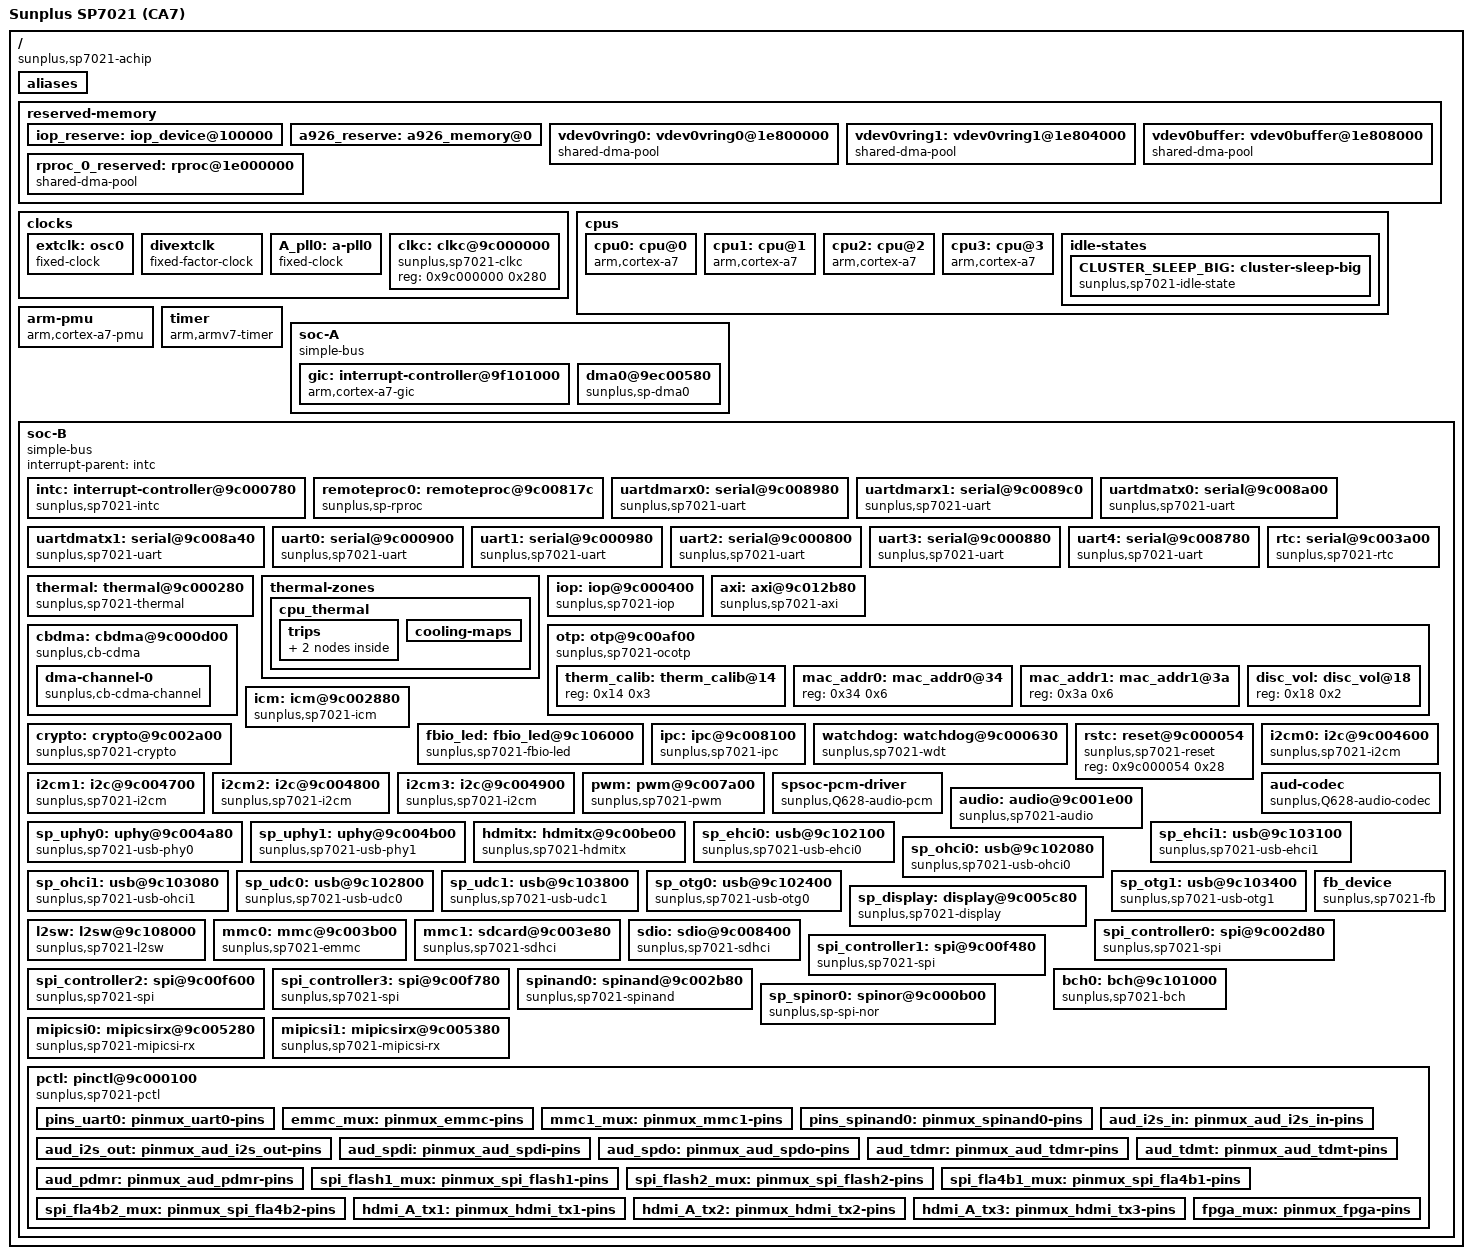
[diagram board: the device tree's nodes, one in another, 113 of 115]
// SPDX-License-Identifier: GPL-2.0
/*
 * Device Tree Source (include) for Sunplus SP7021 SoC
 *                (Common portion)
 *
 * Copyright (C) 2021 Sunplus Technology Co.
 */

/dts-v1/;

#include <dt-bindings/clock/sp-sp7021.h>
#include <dt-bindings/interrupt-controller/arm-gic.h>
#include <dt-bindings/interrupt-controller/sp7021-intc.h>
#include <dt-bindings/interrupt-controller/irq.h>
#include <dt-bindings/reset/sp-sp7021.h>
#include <dt-bindings/gpio/gpio.h>
#include <dt-bindings/pinctrl/sppctl-sp7021.h>

#ifndef ENABLE_DMARX0
#define ENABLE_DMARX0 1
#endif
#ifndef ENABLE_DMARX1
#define ENABLE_DMARX1 1
#endif
#ifndef ENABLE_DMATX0
#define ENABLE_DMATX0 1
#endif
#ifndef ENABLE_DMATX1
#define ENABLE_DMATX1 1
#endif

/ {
	model = "Sunplus SP7021 (CA7)";
	compatible = "sunplus,sp7021-achip";

	interrupt-parent = <&gic>;

	#address-cells = <1>;
	#size-cells = <1>;

	aliases {
#ifdef ENABLE_DMARX0
		serial10 = &uartdmarx0;
#endif
#ifdef ENABLE_DMARX1
		serial11 = &uartdmarx1;
#endif
#ifdef ENABLE_DMATX0
		serial20 = &uartdmatx0;
#endif
#ifdef ENABLE_DMATX1
		serial21 = &uartdmatx1;
#endif

		serial0 = &uart0;
		serial1 = &uart1;
		serial2 = &uart2;
		serial3 = &uart3;
		serial4 = &uart4;

#if 0
		/* Timer tests: */
		/* 1. Enable device tree for timers. */
		/* 2. Enable sp_timer_test in drivers/misc/Makefile */
		stc0 = &sp_tmr_tst0;
		stc1 = &sp_tmr_tst1;
		stc2 = &sp_tmr_tst2;
		stc3 = &sp_tmr_tst3;
#endif

		i2c0 = &i2cm0;
		i2c1 = &i2cm1;
		i2c2 = &i2cm2;
		i2c3 = &i2cm3;

		sp-spi0 = &spi_controller0;
		sp-spi1 = &spi_controller1;
		sp-spi2 = &spi_controller2;
		sp-spi3 = &spi_controller3;

		spi0 = &sp_spinor0;
	};

	reserved-memory {
		#address-cells = <1>;
		#size-cells = <1>;
		ranges;

		iop_reserve: iop_device@100000 {
			reg = <0x00100000 0x00100000>;  // SP_IOP_RESERVE_BASE SP_IOP_RESERVE_SIZE
			no-map;
		};

		a926_reserve: a926_memory@0 {
			reg = <0x00000000 0x00100000>;
			no-map;
		};

		/* reserved for remoteproc */
		vdev0vring0: vdev0vring0@1e800000 {
			compatible = "shared-dma-pool";
			reg = <0x1e800000 0x4000>;
			no-map;
		};
		vdev0vring1: vdev0vring1@1e804000 {
			compatible = "shared-dma-pool";
			reg = <0x1e804000 0x4000>;
			no-map;
		};
		vdev0buffer: vdev0buffer@1e808000 {
			compatible = "shared-dma-pool";
			reg = <0x1e808000 0x100000>;
			no-map;
		};
		rproc_0_reserved: rproc@1e000000 {
			compatible = "shared-dma-pool";
			reg = <0x1e000000 0x800000>;
			no-map;
		};
	};

	clocks {
		#address-cells = <1>;
		#size-cells = <1>;
		ranges;

		extclk: osc0 {
			compatible = "fixed-clock";
			#clock-cells = <0>;
			clock-frequency = <27000000>;
			clock-output-names = "extclk";

		};

		divextclk: divextclk {
			compatible = "fixed-factor-clock";
			#clock-cells = <0>;
			clocks  = <&extclk>;
			clock-mult = <1>;
			clock-div = <2>;
			clock-output-names = "extdivclk";
		};

		A_pll0: a-pll0 {
			compatible = "fixed-clock";
			#clock-cells = <0>;
			clock-frequency = <2000000000>;
			clock-output-names = "A_pll0";
		};

		clkc: clkc@9c000000 {
			compatible = "sunplus,sp7021-clkc";
			reg = <0x9c000000 0x280>;
			#clock-cells = <1>;
		};
	};

	cpus {
		#address-cells = <1>;
		#size-cells = <0>;

		cpu0: cpu@0 {
			compatible = "arm,cortex-a7";
			device_type = "cpu";
			reg = <0>;
			clock-frequency = <931000000>;
			cpu-idle-states = <&CLUSTER_SLEEP_BIG>;
		};
		cpu1: cpu@1 {
			compatible = "arm,cortex-a7";
			device_type = "cpu";
			reg = <1>;
			enable-method = "sunplus,sc-smp";
			cpu-boot-reg = <0x9ea7fff0>;
			clock-frequency = <931000000>;
			cpu-idle-states = <&CLUSTER_SLEEP_BIG>;
		};
		cpu2: cpu@2 {
			compatible = "arm,cortex-a7";
			device_type = "cpu";
			reg = <2>;
			enable-method = "sunplus,sc-smp";
			cpu-boot-reg = <0x9ea7ffec>;
			clock-frequency = <931000000>;
			cpu-idle-states = <&CLUSTER_SLEEP_BIG>;
		};
		cpu3: cpu@3 {
			compatible = "arm,cortex-a7";
			device_type = "cpu";
			reg = <3>;
			enable-method = "sunplus,sc-smp";
			cpu-boot-reg = <0x9ea7ffe8>;
			clock-frequency = <931000000>;
			cpu-idle-states = <&CLUSTER_SLEEP_BIG>;
		};

		idle-states {
			CLUSTER_SLEEP_BIG: cluster-sleep-big {
				compatible = "sunplus,sp7021-idle-state";
				//local-timer-stop;
				entry-latency-us = <8000>;
				exit-latency-us = <700>;
				min-residency-us = <9000>;
			};
#if 0
			CLUSTER_SLEEP_LITTLE: cluster-sleep-little {
				compatible = "sunplus,sp7021-idle-state";
				local-timer-stop;
				entry-latency-us = <1000>;
				exit-latency-us = <500>;
				min-residency-us = <2500>;
			};
#endif
		};
	};

	arm-pmu {
		compatible = "arm,cortex-a7-pmu";
		interrupts = <GIC_SPI 219 IRQ_TYPE_LEVEL_HIGH>,
			     <GIC_SPI 220 IRQ_TYPE_LEVEL_HIGH>,
			     <GIC_SPI 221 IRQ_TYPE_LEVEL_HIGH>,
			     <GIC_SPI 222 IRQ_TYPE_LEVEL_HIGH>;
		interrupt-affinity = <&cpu0>, <&cpu1>, <&cpu2>, <&cpu3>;
	};

	timer: timer {
		compatible = "arm,armv7-timer";
		interrupts = <GIC_PPI 13 (GIC_CPU_MASK_SIMPLE(4) | IRQ_TYPE_LEVEL_LOW)>,
			     <GIC_PPI 14 (GIC_CPU_MASK_SIMPLE(4) | IRQ_TYPE_LEVEL_LOW)>,
			     <GIC_PPI 11 (GIC_CPU_MASK_SIMPLE(4) | IRQ_TYPE_LEVEL_LOW)>,
			     <GIC_PPI 10 (GIC_CPU_MASK_SIMPLE(4) | IRQ_TYPE_LEVEL_LOW)>;
		clock-frequency = <27000000>;
		arm,cpu-registers-not-fw-configured;
	};

	/* A modules */
	soc-A {
		compatible = "simple-bus";
		#address-cells = <1>;
		#size-cells = <1>;
		ranges;

		gic: interrupt-controller@9f101000 {
			compatible = "arm,cortex-a7-gic";
			reg = <0x9f101000 0x1000>, <0x9f102000 0x2000>, <0x9f104000 0x2000>, <0x9f106000 0x2000>;
			interrupt-controller;
			#interrupt-cells = <3>;
		};

		dma0@9ec00580 {
			compatible = "sunplus,sp-dma0";
			reg = <0x9ec00580 0x180>; /* G11 ~ G13 */
			interrupt-parent = <&gic>;
			interrupts = <GIC_SPI 8  IRQ_TYPE_EDGE_RISING>, /* ch0_job_done */
				     <GIC_SPI 9  IRQ_TYPE_EDGE_RISING>, /* ch1_job_done */
				     <GIC_SPI 10 IRQ_TYPE_EDGE_RISING>, /* ch2_job_done */
				     <GIC_SPI 11 IRQ_TYPE_EDGE_RISING>, /* ch3_job_done */
				     <GIC_SPI 12 IRQ_TYPE_EDGE_RISING>, /* ch4_job_done */
				     <GIC_SPI 13 IRQ_TYPE_EDGE_RISING>, /* ch5_job_done */
				     <GIC_SPI 14 IRQ_TYPE_EDGE_RISING>, /* ch6_job_done */
				     <GIC_SPI 15 IRQ_TYPE_EDGE_RISING>, /* ch7_job_done */
				     <GIC_SPI 16 IRQ_TYPE_EDGE_RISING>; /* addr_exp_err */
		};
#if 0
		/* Each Cortex A-7 has its own system timer, it's not required if armv7-timer is enabled. */
		/* This timer will be used in sp_timer_test.c */
		timer@9ec00980 {
			compatible = "sunplus,sp-stc";
			reg = <0x9ec00980 0x80>;
			interrupt-parent = <&gic>;
			interrupts = <GIC_SPI 1 IRQ_TYPE_EDGE_RISING>, /* timer0 */
				     <GIC_SPI 2 IRQ_TYPE_EDGE_RISING>, /* timer1 */
				     <GIC_SPI 3 IRQ_TYPE_EDGE_RISING>, /* timer2 */
				     <GIC_SPI 4 IRQ_TYPE_EDGE_RISING>; /* timer3 */
		};
#endif
#if 0
		sp_tmr_tst@9ec00980 {
			compatible = "sunplus,sp-tmr-tst";
			reg = <0x9ec00980 0x80>;
			interrupt-parent = <&gic>;
			interrupts = <GIC_SPI 1 IRQ_TYPE_EDGE_RISING>, /* timer0 */
				     <GIC_SPI 2 IRQ_TYPE_EDGE_RISING>, /* timer1 */
				     <GIC_SPI 3 IRQ_TYPE_EDGE_RISING>, /* timer2 */
				     <GIC_SPI 4 IRQ_TYPE_EDGE_RISING>; /* timer3 */
		};
#endif
#if 0
		axi: axi@sp_axi {
			compatible = "sunplus,sp7021-axi";
			reg = <0x9ec12b80 0x80>, <0x9ec12c00 0x80>, <0x9ec12c80 0x80>,
			      <0x9ec12d00 0x80>, <0x9ec12d80 0x80>, <0x9ec12e00 0x80>,
			      <0x9ec12e80 0x80>, <0x9ec12f00 0x80>, <0x9ec12f80 0x80>,
			      <0x9ec13000 0x80>, <0x9ec13080 0x80>, <0x9ec13100 0x80>,
			      <0x9c000d00 0x80>;
			reg-names = "axi_mon", "axi_0", "axi_1",
				    "axi_2", "axi_3", "axi_4",
				    "axi_5", "axi_6", "axi_7",
				    "axi_8", "axi_9", "axi_10",
				    "axi_cbdma";
			interrupt-parent = <&gic>;
			interrupts = <GIC_SPI 23 IRQ_TYPE_EDGE_RISING>;
			clocks = <&clkc AXI_GLOBAL>;
			resets = <&rstc RST_AXI_GLOBAL>;
		};
#endif
	};

	/* B modules */
	soc-B {
		compatible = "simple-bus";
		#address-cells = <1>;
		#size-cells = <1>;
		ranges;

		interrupt-parent = <&intc>;

		intc: interrupt-controller@9c000780 {
			compatible = "sunplus,sp7021-intc";
			interrupt-controller;
			#interrupt-cells = <2>;
			reg = <0x9c000780 0x80>, <0x9c000a80 0x80>;
			interrupt-parent = <&gic>;
			interrupts = <GIC_SPI 5 IRQ_TYPE_LEVEL_HIGH>, /* EXT_INT0 */
				     <GIC_SPI 6 IRQ_TYPE_LEVEL_HIGH>; /* EXT_INT1 */
			sunplus,ext0-mask = <0xf>; /* core0-3 */
			sunplus,ext1-mask = <0xe>; /* core1-3 */
		};

		remoteproc0: remoteproc@9c00817c {
			compatible = "sunplus,sp-rproc";
			firmware = "firmware";
			reg = <0x9c00817c 4>, /* mbox G258.31 */
				<0x9e809ff8 4>; /* boot A926 */
			interrupt-parent = <&intc>;
			interrupts = <189 IRQ_TYPE_EDGE_RISING>; /* ACHIPCPU0_DIRECT_INT7 */
			resets = <&rstc RST_A926>;
			memory-region = <&rproc_0_reserved>, <&vdev0buffer>, <&vdev0vring0>, <&vdev0vring1>;
		};

#ifdef ENABLE_DMARX0
		/* DMA Rx for UARTx */
		uartdmarx0: serial@9c008980 {
			compatible = "sunplus,sp7021-uart";
			reg = <0x9c008980 0x40>;
			interrupt-parent = <&intc>;
			interrupts = <138 IRQ_TYPE_LEVEL_HIGH>;
			clocks = <&clkc UADMA>, <&clkc PERI0>;
			clock-names = "UADMA", "PERI0";
			resets = <&rstc RST_UADMA>;
			which-uart = <1>;
		};
#endif
#ifdef ENABLE_DMARX1
		uartdmarx1: serial@9c0089c0 {
			compatible = "sunplus,sp7021-uart";
			reg = <0x9c0089c0 0x40>;
			interrupt-parent = <&intc>;
			interrupts = <139 IRQ_TYPE_LEVEL_HIGH>;
			clocks = <&clkc UADMA>,	<&clkc PERI1>;
			clock-names = "UADMA", "PERI1";
			resets = <&rstc RST_UADMA>;
			which-uart = <2>;
		};
#endif
#ifdef ENABLE_DMATX0
		/* DMA Tx for UARTx */
		uartdmatx0: serial@9c008a00 {
			compatible = "sunplus,sp7021-uart";
			reg = <0x9c008a00 0x40>, <0x9c008880 0x80>;
			clocks = <&clkc HWUA>, <&clkc PERI0>;
			clock-names = "HWUA", "PERI0";
			resets = <&rstc RST_HWUA>;
			which-uart = <1>;
		};
#endif
#ifdef ENABLE_DMATX1
		uartdmatx1: serial@9c008a40 {
			compatible = "sunplus,sp7021-uart";
			reg = <0x9c008a40 0x40>, <0x9c008900 0x80>;
			clocks = <&clkc HWUA>, <&clkc PERI1>;
			clock-names = "HWUA", "PERI1";
			resets = <&rstc RST_HWUA>;
			which-uart = <2>;
		};
#endif

		uart0: serial@9c000900 {
			compatible = "sunplus,sp7021-uart";
			reg = <0x9c000900 0x80>;
			interrupt-parent = <&intc>;
			interrupts = <53 IRQ_TYPE_LEVEL_HIGH>;
			clocks = <&clkc UA0>;
			resets = <&rstc RST_UA0>;
			pinctrl-names = "default";
			pinctrl-0 = <&pins_uart0>;
		};

		uart1: serial@9c000980 {
			compatible = "sunplus,sp7021-uart";
			reg = <0x9c000980 0x80>;
			interrupt-parent = <&intc>;
			interrupts = <54 IRQ_TYPE_LEVEL_HIGH>;
			clocks = <&clkc UA1>;
			resets = <&rstc RST_UA1>;
		};

		uart2: serial@9c000800 {
			compatible = "sunplus,sp7021-uart";
			reg = <0x9c000800 0x80>;
			interrupt-parent = <&intc>;
			interrupts = <55 IRQ_TYPE_LEVEL_HIGH>;
			clocks = <&clkc UA2>;
			resets = <&rstc RST_UA2>;
		};

		uart3: serial@9c000880 {
			compatible = "sunplus,sp7021-uart";
			reg = <0x9c000880 0x80>;
			interrupt-parent = <&intc>;
			interrupts = <56 IRQ_TYPE_LEVEL_HIGH>;
			clocks = <&clkc UA3>;
			resets = <&rstc RST_UA3>;
		};

		uart4: serial@9c008780 {
			compatible = "sunplus,sp7021-uart";
			reg = <0x9c008780 0x80>;
			interrupt-parent = <&intc>;
			interrupts = <134 IRQ_TYPE_LEVEL_HIGH>;
			clocks = <&clkc UA4>;
			resets = <&rstc RST_UA4>;
		};

		rtc: serial@9c003a00 {
			compatible = "sunplus,sp7021-rtc";
			reg = <0x9c003a00 0x80>;
			reg-names = "rtc_reg";
			clocks = <&clkc RTC>;
			resets = <&rstc RST_RTC>;
			interrupt-parent = <&intc>;
			interrupts = <163 IRQ_TYPE_EDGE_RISING>;
		};

		thermal: thermal@9c000280 {
			compatible = "sunplus,sp7021-thermal";
			reg = <0x9c000280 0x80>;
			#thermal-sensor-cells = <0>;
			nvmem-cell-names = "therm_calib";
			nvmem-cells = <&therm_calib>;
		};

		thermal-zones {
			cpu_thermal: cpu_thermal {
				polling-delay-passive = <1000>; /* milliseconds */
				polling-delay = <1000>; /* milliseconds */

				thermal-sensors = <&thermal 0>;
				sustainable-power = <100000>;

				trips {
					cpu-hott {
						temperature = <80000>;
						hysteresis  = <1000>;
						type        = "hot";
					};
					cpu-crit {
						temperature = <85000>;
						hysteresis  = <0>;
						type        = "critical";
					};
				};
				cooling-maps {
					/* insert there: slowdown CPU for cpu-hott */
				};
			};
		};

		iop: iop@9c000400 {
			compatible = "sunplus,sp7021-iop";
			reg = <0x9c000400 0x80>, <0x9c000000 0x80>, <0x9c000f00 0x80>, <0x9c003100 0x80>, <0x9c012b80 0x80>;
			reg-names = "iop", "iop_moon0", "iop_qctl", "iop_pmc", "axi_mon";
			interrupt-parent = <&intc>;
			interrupts = <41 IRQ_TYPE_LEVEL_HIGH>, <42 IRQ_TYPE_LEVEL_HIGH>;
			memory-region = <&iop_reserve>;
		};

		axi: axi@9c012b80 {
			compatible = "sunplus,sp7021-axi";
			reg = <0x9c012b80 0x80>, <0x9c012e00 0x80>, <0x9c012e80 0x80>,
			      <0x9c013200 0x80>, <0x9c013680 0x80>, <0x9c013700 0x80>,
			      <0x9c013980 0x80>, <0x9c013a00 0x80>, <0x9c013b80 0x80>,
			      <0x9c013c00 0x80>, <0x9c013c80 0x80>, <0x9c013d00 0x80>,
			      <0x9c014080 0x80>, <0x9c014100 0x80>, <0x9c014180 0x80>,
			      <0x9c014280 0x80>, <0x9c014300 0x80>, <0x9c014380 0x80>,
			      <0x9c014480 0x80>, <0x9c000d00 0x80>;
			reg-names = "axi_mon", "axi_4", "axi_5",
				    "axi_12", "axi_21", "axi_22",
				    "axi_27", "axi_28", "axi_31",
				    "axi_32", "axi_33", "axi_34",
				    "axi_41", "axi_42", "axi_43",
				    "axi_45", "axi_46", "axi_47",
				    "axi_49", "axi_cbdma";
			interrupt-parent = <&intc>;
			interrupts = <103 IRQ_TYPE_LEVEL_HIGH>;
			clocks = <&clkc AXI_GLOBAL>;
			resets = <&rstc RST_AXI_GLOBAL>;
		};

		otp: otp@9c00af00 {
			compatible = "sunplus,sp7021-ocotp";
			reg = <0x9c00af00 0x34>, <0x9c00af80 0x58>;
			reg-names = "hb_gpio", "otprx";
			clocks = <&clkc OTPRX>;
			resets = <&rstc RST_OTPRX>;
			#address-cells = <1>;
			#size-cells = <1>;
			therm_calib: therm_calib@14 {
				reg = <0x14 0x3>;
			};
			mac_addr0: mac_addr0@34 {
				reg = <0x34 0x6>;
			};
			mac_addr1: mac_addr1@3a {
				reg = <0x3a 0x6>;
			};
			disc_vol: disc_vol@18 {
				reg = <0x18 0x2>;
			};
		};

		cbdma: cbdma@9c000d00 {
			compatible = "sunplus,cb-cdma";
			reg = <0x9c000d00 0x80>;
			reg-names = "cb_dma";
			interrupt-parent = <&intc>;
			interrupts = <128 IRQ_TYPE_LEVEL_HIGH>;
			addrwidth = <0x20>;
			dma-channel-0 {
				compatible = "sunplus,cb-cdma-channel";
				interrupts = <128 IRQ_TYPE_LEVEL_HIGH>;
				datawidth = <0x20>;
			};
		};

		icm: icm@9c002880 {
			compatible = "sunplus,sp7021-icm";
			clocks = <&clkc ICM>;
			resets = <&rstc RST_ICM>;
			reg = <0x9c002880 0x80>;
			interrupt-parent = <&intc>;
			interrupts =
				<92 IRQ_TYPE_EDGE_RISING>, /* icm0 */
				<93 IRQ_TYPE_EDGE_RISING>, /* icm1 */
				<94 IRQ_TYPE_EDGE_RISING>, /* icm2 */
				<95 IRQ_TYPE_EDGE_RISING>; /* icm3 */
		};

		fbio_led: fbio_led@9c106000 {
			compatible = "sunplus,sp7021-fbio-led";
			clocks = <&clkc FIO_CTL>, <&clkc FPGA>;
			clock-names = "fio", "fpga";
			resets = <&rstc RST_FPGA>;
			reg = <0x9c106000 0x80>, <0x70000000 0x10>;
			interrupt-parent = <&intc>;
			interrupts = <29 IRQ_TYPE_EDGE_RISING>; /* fpga_ext0 */
		};

		crypto: crypto@9c002a00 {
			compatible = "sunplus,sp7021-crypto";
			reg = <0x9c002a00 0x100>; /* G84 ~ G85 */
			clocks = <&clkc SEC>;
			resets = <&rstc RST_SEC>;
			interrupt-parent = <&intc>;
			interrupts = <148 IRQ_TYPE_LEVEL_HIGH>;
		};

		ipc: ipc@9c008100 {
			compatible = "sunplus,sp7021-ipc";
			reg = <0x9c008100 0x100>; /* G258 ~ G259 */
			interrupt-parent = <&intc>;
			interrupts =
				<182 IRQ_TYPE_EDGE_RISING>, /* ACHIPCPU0_DIRECT_INT0 */
				<183 IRQ_TYPE_EDGE_RISING>, /* ACHIPCPU0_DIRECT_INT1 */
				<184 IRQ_TYPE_EDGE_RISING>, /* ACHIPCPU0_DIRECT_INT2 */
				<185 IRQ_TYPE_EDGE_RISING>, /* ACHIPCPU0_DIRECT_INT3 */
				<186 IRQ_TYPE_EDGE_RISING>, /* ACHIPCPU0_DIRECT_INT4 */
				<187 IRQ_TYPE_EDGE_RISING>, /* ACHIPCPU0_DIRECT_INT5 */
				<188 IRQ_TYPE_EDGE_RISING>, /* ACHIPCPU0_DIRECT_INT6 */
				<189 IRQ_TYPE_EDGE_RISING>, /* ACHIPCPU0_DIRECT_INT7 */
				<190 IRQ_TYPE_EDGE_RISING>, /* A926_DIRECT_INT0 */
				<191 IRQ_TYPE_EDGE_RISING>, /* A926_DIRECT_INT1 */
				<192 IRQ_TYPE_EDGE_RISING>, /* A926_DIRECT_INT2 */
				<193 IRQ_TYPE_EDGE_RISING>, /* A926_DIRECT_INT3 */
				<194 IRQ_TYPE_EDGE_RISING>, /* A926_DIRECT_INT4 */
				<195 IRQ_TYPE_EDGE_RISING>, /* A926_DIRECT_INT5 */
				<196 IRQ_TYPE_EDGE_RISING>, /* A926_DIRECT_INT6 */
				<197 IRQ_TYPE_EDGE_RISING>, /* A926_DIRECT_INT7 */
				<198 IRQ_TYPE_EDGE_RISING>, /* ACHIPCPU0_INT */
				<199 IRQ_TYPE_EDGE_RISING>; /* A926_INT */
		};

		watchdog: watchdog@9c000630 {
			compatible = "sunplus,sp7021-wdt";
			reg = <0x9c000630 0x08>, <0x9c000274 0x04>;
			clocks = <&clkc STC0>;
			resets = <&rstc RST_STC0>;
		};

/* Timer tests: */
/* 1. Enable device tree for timers. */
/* 2. Enable sp_timer_test in drivers/misc/Makefile */
#if 0
		sp_tmr_tst0: sp_tmr_tst@9c000600 {
			compatible = "sunplus,sp-tmr-tst";
			reg = <0x9c000600 0x80>;
			interrupt-parent = <&intc>;
			interrupts =
				<151 IRQ_TYPE_EDGE_RISING>, /* timer0 */
				<152 IRQ_TYPE_EDGE_RISING>, /* timer1 */
				<153 IRQ_TYPE_EDGE_RISING>, /* timer2 */
				<154 IRQ_TYPE_EDGE_RISING>; /* timer3 */
			clocks = <&clkc STC0>;
			resets = <&rstc RST_STC0>;
		};

		sp_tmr_tst1: sp_tmr_tst@9c003000 {
			compatible = "sunplus,sp-tmr-tst";
			reg = <0x9c003000 0x80>;
			interrupt-parent = <&intc>;
			interrupts =
				<155 IRQ_TYPE_EDGE_RISING>, /* timer0 */
				<156 IRQ_TYPE_EDGE_RISING>, /* timer1 */
				<157 IRQ_TYPE_EDGE_RISING>, /* timer2 */
				<158 IRQ_TYPE_EDGE_RISING>; /* timer3 */
			clocks = <&clkc STC_AV0>;
			resets = <&rstc RST_STC_AV0>;
		};

		sp_tmr_tst2: sp_tmr_tst@9c003080 {
			compatible = "sunplus,sp-tmr-tst";
			reg = <0x9c003080 0x80>;
			interrupt-parent = <&intc>;
			interrupts =
				<159 IRQ_TYPE_EDGE_RISING>, /* timer0 */
				<160 IRQ_TYPE_EDGE_RISING>, /* timer1 */
				<161 IRQ_TYPE_EDGE_RISING>, /* timer2 */
				<162 IRQ_TYPE_EDGE_RISING>; /* timer3 */
			clocks = <&clkc STC_AV1>;
			resets = <&rstc RST_STC_AV1>;
		};

		sp_tmr_tst3: sp_tmr_tst@9c003180 {
			compatible = "sunplus,sp-tmr-tst";
			reg = <0x9c003180 0x80>;
			interrupt-parent = <&intc>;
			interrupts =
				<164 IRQ_TYPE_EDGE_RISING>, /* timer0 */
				<165 IRQ_TYPE_EDGE_RISING>, /* timer1 */
				<166 IRQ_TYPE_EDGE_RISING>, /* timer2 */
				<167 IRQ_TYPE_EDGE_RISING>; /* timer3 */
			clocks = <&clkc STC_AV2>;
			resets = <&rstc RST_STC_AV2>;
		};
#endif

		rstc: reset@9c000054 {
			compatible = "sunplus,sp7021-reset";
			#reset-cells = <1>;
			reg = <0x9c000054 0x28>;
			reg-names = "reset";
		};

		i2cm0: i2c@9c004600 {
			compatible = "sunplus,sp7021-i2cm";
			reg = <0x9c004600 0x80>, <0x9c004680 0x80>, <0x9c000000 0x80>;
			reg-names = "i2cm", "i2cmdma", "i2cdmapower";
			interrupt-parent = <&intc>;
			interrupts = <174 IRQ_TYPE_LEVEL_HIGH>;
			clocks = <&clkc I2CM0>;
			resets = <&rstc RST_I2CM0>;
		};

		i2cm1: i2c@9c004700 {
			compatible = "sunplus,sp7021-i2cm";
			reg = <0x9c004700 0x80>, <0x9c004780 0x80>, <0x9c000000 0x80>;
			reg-names = "i2cm", "i2cmdma", "i2cdmapower";
			interrupt-parent = <&intc>;
			interrupts = <175 IRQ_TYPE_LEVEL_HIGH>;
			clocks = <&clkc I2CM1>;
			resets = <&rstc RST_I2CM1>;
		};

		i2cm2: i2c@9c004800 {
			compatible = "sunplus,sp7021-i2cm";
			reg = <0x9c004800 0x80>, <0x9c004880 0x80>, <0x9c000000 0x80>;
			reg-names = "i2cm", "i2cmdma", "i2cdmapower";
			interrupt-parent = <&intc>;
			interrupts = <176 IRQ_TYPE_LEVEL_HIGH>;
			clocks = <&clkc I2CM2>;
			resets = <&rstc RST_I2CM2>;
		};

		i2cm3: i2c@9c004900 {
			compatible = "sunplus,sp7021-i2cm";
			reg = <0x9c004900 0x80>, <0x9c004980 0x80>, <0x9c000000 0x80>;
			reg-names = "i2cm", "i2cmdma", "i2cdmapower";
			interrupt-parent = <&intc>;
			interrupts = <177 IRQ_TYPE_LEVEL_HIGH>;
			clocks = <&clkc I2CM3>;
			resets = <&rstc RST_I2CM3>;
		};

		pwm: pwm@9c007a00 {
			#pwm-cells = <2>;
			compatible = "sunplus,sp7021-pwm";
			reg = <0x9c007a00 0x80>;
			clocks = <&clkc DISP_PWM>;
			resets = <&rstc RST_DISP_PWM>;
		};

		spsoc-pcm-driver {
			compatible = "sunplus,Q628-audio-pcm";
		};

		aud-codec {
			compatible = "sunplus,Q628-audio-codec";
		};

		audio: audio@9c001e00 {
			compatible = "sunplus,sp7021-audio";
			reg = <0x9c001e00 0x680>;
			reg-names = "audio";
			clocks = <&clkc AUD>, <&clkc PERI0>, <&clkc PLL_A>;
			clock-names = "aud","peri0","pll_a";
			resets = <&rstc RST_AUD>;
		};

		sp_uphy0: uphy@9c004a80 {
			compatible = "sunplus,sp7021-usb-phy0";
			clocks = <&clkc UPHY0>;
			resets = <&rstc RST_UPHY0>;
			reg = <0x9c004a80 0x80>, <0x9c000000 0x80>, <0x9c000200 0x80>;
			interrupt-parent = <&intc>;
			interrupts = <36 IRQ_TYPE_LEVEL_HIGH>;
			nvmem-cell-names = "disc_vol";
			nvmem-cells = <&disc_vol>;
		};

		sp_uphy1: uphy@9c004b00 {
			compatible = "sunplus,sp7021-usb-phy1";
			clocks = <&clkc UPHY1>;
			resets = <&rstc RST_UPHY1>;
			reg = <0x9c004b00 0x80>, <0x9c000000 0x80>, <0x9c000200 0x80>;
			interrupt-parent = <&intc>;
			interrupts = <37 IRQ_TYPE_LEVEL_HIGH>;
			nvmem-cell-names = "disc_vol";
			nvmem-cells = <&disc_vol>;
		};

		hdmitx: hdmitx@9c00be00 {
			compatible = "sunplus,sp7021-hdmitx";
			clocks = <&clkc HDMI_TX>;
			resets = <&rstc RST_HDMI_TX>;
			reg = <0x9c00be00 0x3fc>, <0x9c000238 0xc>, <0x9c000290 0x4>;
			interrupt-parent = <&intc>;
			interrupts = <105 IRQ_TYPE_LEVEL_HIGH>;
		};

		sp_ehci0: usb@9c102100 {
			compatible = "sunplus,sp7021-usb-ehci0";
			clocks = <&clkc USBC0>;
			resets = <&rstc RST_USBC0>;
			reg = <0x9c102100 0x68>;
			interrupt-parent = <&intc>;
			interrupts = <14 IRQ_TYPE_LEVEL_HIGH>;
		};

		sp_ehci1: usb@9c103100 {
			compatible = "sunplus,sp7021-usb-ehci1";
			clocks = <&clkc USBC1>;
			resets = <&rstc RST_USBC1>;
			reg = <0x9c103100 0x68>;
			interrupt-parent = <&intc>;
			interrupts = <17 IRQ_TYPE_LEVEL_HIGH>;
		};

		sp_ohci0: usb@9c102080 {
			compatible = "sunplus,sp7021-usb-ohci0";
			clocks = <&clkc USBC0>;
			resets = <&rstc RST_USBC0>;
			reg = <0x9c102080 0x68>, <0x9c000000 0x80>;
			interrupt-parent = <&intc>;
			interrupts = <15 IRQ_TYPE_LEVEL_HIGH>;
		};

		sp_ohci1: usb@9c103080 {
			compatible = "sunplus,sp7021-usb-ohci1";
			clocks = <&clkc USBC1>;
			resets = <&rstc RST_USBC1>;
			reg = <0x9c103080 0x68>, <0x9c000000 0x80>;
			interrupt-parent = <&intc>;
			interrupts = <18 IRQ_TYPE_LEVEL_HIGH>;
		};

		sp_udc0: usb@9c102800 {
			compatible = "sunplus,sp7021-usb-udc0";
			clocks = <&clkc USBC0>;
			resets = <&rstc RST_USBC0>;
			reg = <0x9c102800 0x400>;
			interrupt-parent = <&intc>;
			interrupts = <13 IRQ_TYPE_LEVEL_HIGH>;
		};

		sp_udc1: usb@9c103800 {
			compatible = "sunplus,sp7021-usb-udc1";
			clocks = <&clkc USBC1>;
			resets = <&rstc RST_USBC1>;
			reg = <0x9c103800 0x400>;
			interrupt-parent = <&intc>;
			interrupts = <16 IRQ_TYPE_LEVEL_HIGH>;
		};

		sp_otg0: usb@9c102400 {
			compatible = "sunplus,sp7021-usb-otg0";
			reg = <0x9c102400 0x70>, <0x9c000200 0x80>;
			interrupt-parent = <&intc>;
			interrupts = <11 IRQ_TYPE_LEVEL_HIGH>;
		};

		sp_otg1: usb@9c103400 {
			compatible = "sunplus,sp7021-usb-otg1";
			reg = <0x9c103400 0x70>, <0x9c000200 0x80>;
			interrupt-parent = <&intc>;
			interrupts = <10 IRQ_TYPE_LEVEL_HIGH>;
		};

		fb_device {
			compatible = "sunplus,sp7021-fb";
		};

		sp_display: display@9c005c80 {
			compatible = "sunplus,sp7021-display";
			reg = <0x9c005c80 0x1980>, <0x9c105000 0x80>;
			interrupt-parent = <&intc>;
			interrupts = <0 (IRQ_TYPE_EDGE_RISING | SP_INTC_EXT_INT1)>,
				     <1 (IRQ_TYPE_EDGE_RISING | SP_INTC_EXT_INT1)>,
				     <4 (IRQ_TYPE_EDGE_RISING | SP_INTC_EXT_INT1)>,
				     <5 (IRQ_TYPE_EDGE_RISING | SP_INTC_EXT_INT1)>;
			clocks = <&clkc TGEN>,
				 <&clkc DMIX>,
				 <&clkc OSD0>,
				 <&clkc GPOST0>,
				 <&clkc VPOST>,
				 <&clkc DDFCH>,
				 <&clkc DVE>,
				 <&clkc HDMI_TX>;
			clock-names = "DISP_TGEN",
				      "DISP_DMIX",
				      "DISP_OSD0",
				      "DISP_GPOST0",
				      "DISP_VPOST",
				      "DISP_DDFCH",
				      "DISP_DVE",
				      "DISP_HDMI";
			resets = <&rstc RST_TGEN>,
				 <&rstc RST_DMIX>,
				 <&rstc RST_OSD0>,
				 <&rstc RST_GPOST0>,
				 <&rstc RST_VPOST>,
				 <&rstc RST_DDFCH>,
				 <&rstc RST_DVE>,
				 <&rstc RST_HDMI_TX>;
		};

		l2sw: l2sw@9c108000 {
			compatible = "sunplus,sp7021-l2sw";
			reg = <0x9c108000 0x400>;
			interrupt-parent = <&intc>;
			interrupts = <66 IRQ_TYPE_LEVEL_HIGH>;
			clocks = <&clkc L2SW>;
			resets = <&rstc RST_L2SW>;
			nvmem-cell-names = "mac_addr0", "mac_addr1";
			nvmem-cells = <&mac_addr0>, <&mac_addr1>;
		};

		mmc0: mmc@9c003b00 {
			compatible = "sunplus,sp7021-emmc";
			reg = <0x9c003b00 0x180>;
			interrupts = <20 IRQ_TYPE_LEVEL_HIGH>;
			clocks = <&clkc CARD_CTL0>;
			resets = <&rstc RST_CARD_CTL0>;
			bus-width = <8>;
			max-frequency = <52000000>;
			non-removable;
			disable-wp;
			cap-mmc-highspeed;
			mmc-ddr-3_3v;
			no-sdio;
			no-sd;
		};

		mmc1: sdcard@9c003e80 {
			compatible = "sunplus,sp7021-sdhci";
			reg = <0x9c003e80 0x280>;
			interrupts = <21 IRQ_TYPE_LEVEL_HIGH>;
			clocks = <&clkc CARD_CTL1>;
			resets = <&rstc RST_CARD_CTL1>;
			bus-width = <4>;
			max-frequency = <52000000>;
			disable-wp;
			cap-sd-highspeed;
			no-sdio;
			no-mmc;
		};

		sdio: sdio@9c008400 {
			compatible = "sunplus,sp7021-sdhci";
			reg = <0x9c008400 0x280>;
			interrupts = <22 IRQ_TYPE_LEVEL_HIGH>;
			clocks = <&clkc CARD_CTL4>;
			resets = <&rstc RST_CARD_CTL4>;
			bus-width = <4>;
			max-frequency = <52000000>;
			non-removable;
			disable-wp;
			cap-sd-highspeed;
			cap-sdio-irq;
			no-sd;
			no-mmc;
			#address-cells = <1>;
			#size-cells = <0>;
		};

		spi_controller0: spi@9c002d80 {
			compatible = "sunplus,sp7021-spi";
			reg = <0x9c002d80 0x80>, <0x9c002e00 0x80>;
			reg-names = "master", "slave";
			interrupt-parent = <&intc>;
			interrupt-names = "dma_w",
					  "master_risc",
					  "slave_risc";
			interrupts = <144 IRQ_TYPE_LEVEL_HIGH>,
				     <146 IRQ_TYPE_LEVEL_HIGH>,
				     <145 IRQ_TYPE_LEVEL_HIGH>;
			clocks = <&clkc SPI_COMBO_0>;
			resets = <&rstc RST_SPI_COMBO_0>;
		};

		spi_controller1: spi@9c00f480 {
			compatible = "sunplus,sp7021-spi";
			reg = <0x9c00f480 0x80>, <0x9c00f500 0x80>;
			reg-names = "master", "slave";
			interrupt-parent = <&intc>;
			interrupt-names = "dma_w",
					  "master_risc",
					  "slave_risc";
			interrupts = <67 IRQ_TYPE_LEVEL_HIGH>,
				     <69 IRQ_TYPE_LEVEL_HIGH>,
				     <68 IRQ_TYPE_LEVEL_HIGH>;
			clocks = <&clkc SPI_COMBO_1>;
			resets = <&rstc RST_SPI_COMBO_1>;
		};

		spi_controller2: spi@9c00f600 {
			compatible = "sunplus,sp7021-spi";
			reg = <0x9c00f600 0x80>, <0x9c00f680 0x80>;
			reg-names = "master", "slave";
			interrupt-parent = <&intc>;
			interrupt-names = "dma_w",
					  "master_risc",
					  "slave_risc";
			interrupts = <70 IRQ_TYPE_LEVEL_HIGH>,
				     <72 IRQ_TYPE_LEVEL_HIGH>,
				     <71 IRQ_TYPE_LEVEL_HIGH>;
			clocks = <&clkc SPI_COMBO_2>;
			resets = <&rstc RST_SPI_COMBO_2>;
		};

		spi_controller3: spi@9c00f780 {
			compatible = "sunplus,sp7021-spi";
			reg = <0x9c00f780 0x80>, <0x9c00f800 0x80>;
			reg-names = "master", "slave";
			interrupt-parent = <&intc>;
			interrupt-names = "dma_w",
					  "master_risc",
					  "slave_risc";
			interrupts = <73 IRQ_TYPE_LEVEL_HIGH>,
				     <75 IRQ_TYPE_LEVEL_HIGH>,
				     <74 IRQ_TYPE_LEVEL_HIGH>;
			clocks = <&clkc SPI_COMBO_3>;
			resets = <&rstc RST_SPI_COMBO_3>;
		};

		spinand0: spinand@9c002b80 {
			compatible = "sunplus,sp7021-spinand";
			reg = <0x9c002b80 0x50>;
			interrupt-parent = <&intc>;
			interrupts = <149 IRQ_TYPE_LEVEL_HIGH>;
			clocks = <&clkc SPIND>;
			resets = <&rstc RST_SPIND>;
			spi-max-frequency = <110000000>;
		};

		bch0: bch@9c101000 {
			compatible = "sunplus,sp7021-bch";
			reg = <0x9c101000 0x20>;
			interrupt-parent = <&intc>;
			interrupts = <58 IRQ_TYPE_LEVEL_HIGH>;
			clocks = <&clkc BCH>;
			resets = <&rstc RST_BCH>;
		};

		sp_spinor0: spinor@9c000b00 {
			compatible = "sunplus,sp-spi-nor";
			reg = <0x9c000b00 0x80>;
			interrupt-parent = <&intc>;
			interrupts = <143 IRQ_TYPE_LEVEL_HIGH>;
			clocks = <&clkc SPIFL>;
			resets = <&rstc RST_SPIFL>;
		};

		mipicsi0: mipicsirx@9c005280 {
			compatible = "sunplus,sp7021-mipicsi-rx";
			reg = <0x9c005280 0x80>, <0x9c005300 0x80>;
			reg-names = "mipicsi", "csiiw";
			interrupt-parent = <&intc>;
			interrupts = <49 IRQ_TYPE_EDGE_RISING>,
				     <50 IRQ_TYPE_EDGE_RISING>;
			clocks = <&clkc MIPICSI0>, <&clkc CSIIW0>;
			clock-names = "clk_mipicsi", "clk_csiiw";
			resets = <&rstc RST_MIPICSI0>, <&rstc RST_CSIIW0>;
			reset-names = "rstc_mipicsi", "rstc_csiiw";
		};

		mipicsi1: mipicsirx@9c005380 {
			compatible = "sunplus,sp7021-mipicsi-rx";
			reg = <0x9c005380 0x80>, <0x9c005400 0x80>;
			reg-names = "mipicsi", "csiiw";
			interrupt-parent = <&intc>;
			interrupts = <51 IRQ_TYPE_EDGE_RISING>,
				     <52 IRQ_TYPE_EDGE_RISING>;
			clocks = <&clkc MIPICSI1>, <&clkc CSIIW1>;
			clock-names = "clk_mipicsi", "clk_csiiw";
			resets = <&rstc RST_MIPICSI1>, <&rstc RST_CSIIW1>;
			reset-names = "rstc_mipicsi", "rstc_csiiw";
		};

		pctl: pinctl@9c000100 {
			compatible = "sunplus,sp7021-pctl";
			reg = <0x9c000100 0x100>, <0x9c000300 0x80>, <0x9c000380 0x80>, <0x9c0032e4 0x1c>, <0x9c000080 0x20>;
			reg-names = "moon2", "gpioxt", "gpioxt2", "first", "moon1";
			gpio-controller;
			#gpio-cells = <2>;
			clocks = <&clkc GPIO>;
			resets = <&rstc RST_GPIO>;

			pins_uart0: pinmux_uart0-pins {
				function = "UA0";
				groups = "UA0";
			};

			emmc_mux: pinmux_emmc-pins {
				function = "CARD0_EMMC";
				groups = "CARD0_EMMC";
			};

			mmc1_mux: pinmux_mmc1-pins {
				function = "SD_CARD";
				groups = "SD_CARD";
			};

			pins_spinand0: pinmux_spinand0-pins {
				function = "SPI_NAND";
				groups = "SPI_NAND";
			};

			aud_i2s_in: pinmux_aud_i2s_in-pins {
				function = "AUD_EXT_ADC_IFX0";
				groups = "AUD_EXT_ADC_IFX0";
			};
			aud_i2s_out: pinmux_aud_i2s_out-pins {
				function = "AUD_EXT_DAC_IFX0";
				groups = "AUD_EXT_DAC_IFX0";
			};
			aud_spdi: pinmux_aud_spdi-pins {
				function = "SPDIF_RX";
				groups = "AUD_IEC_RX0";
			};
			aud_spdo: pinmux_aud_spdo-pins {
				function = "SPDIF_TX";
				groups = "AUD_IEC_TX0";
			};
			aud_tdmr: pinmux_aud_tdmr-pins {
				function = "TDMRX_IFX0";
				groups = "TDMRX_IFX0";
			};
			aud_tdmt: pinmux_aud_tdmt-pins {
				function = "TDMTX_IFX0";
				groups = "TDMTX_IFX0";
			};
			aud_pdmr: pinmux_aud_pdmr-pins {
				function = "PDMRX_IFX0";
				groups = "PDMRX_IFX0";
			};

			spi_flash1_mux: pinmux_spi_flash1-pins {
				function = "SPI_FLASH";
				groups = "SPI_FLASH1";
			};
			spi_flash2_mux: pinmux_spi_flash2-pins {
				function = "SPI_FLASH";
				groups = "SPI_FLASH2";
			};

			spi_fla4b1_mux: pinmux_spi_fla4b1-pins {
				function = "SPI_FLASH_4BIT";
				groups = "SPI_FLASH_4BIT1";
			};
			spi_fla4b2_mux: pinmux_spi_fla4b2-pins {
				function = "SPI_FLASH_4BIT";
				groups = "SPI_FLASH_4BIT2";
			};

			hdmi_A_tx1: pinmux_hdmi_tx1-pins {
				function = "HDMI_TX";
				groups = "HDMI_TX1";
			};
			hdmi_A_tx2: pinmux_hdmi_tx2-pins {
				function = "HDMI_TX";
				groups = "HDMI_TX2";
			};
			hdmi_A_tx3: pinmux_hdmi_tx3-pins {
				function = "HDMI_TX";
				groups = "HDMI_TX3";
			};

			fpga_mux: pinmux_fpga-pins {
				function = "FPGA_IFX";
				groups = "FPGA_IFX";
			};
		};
	};
};
